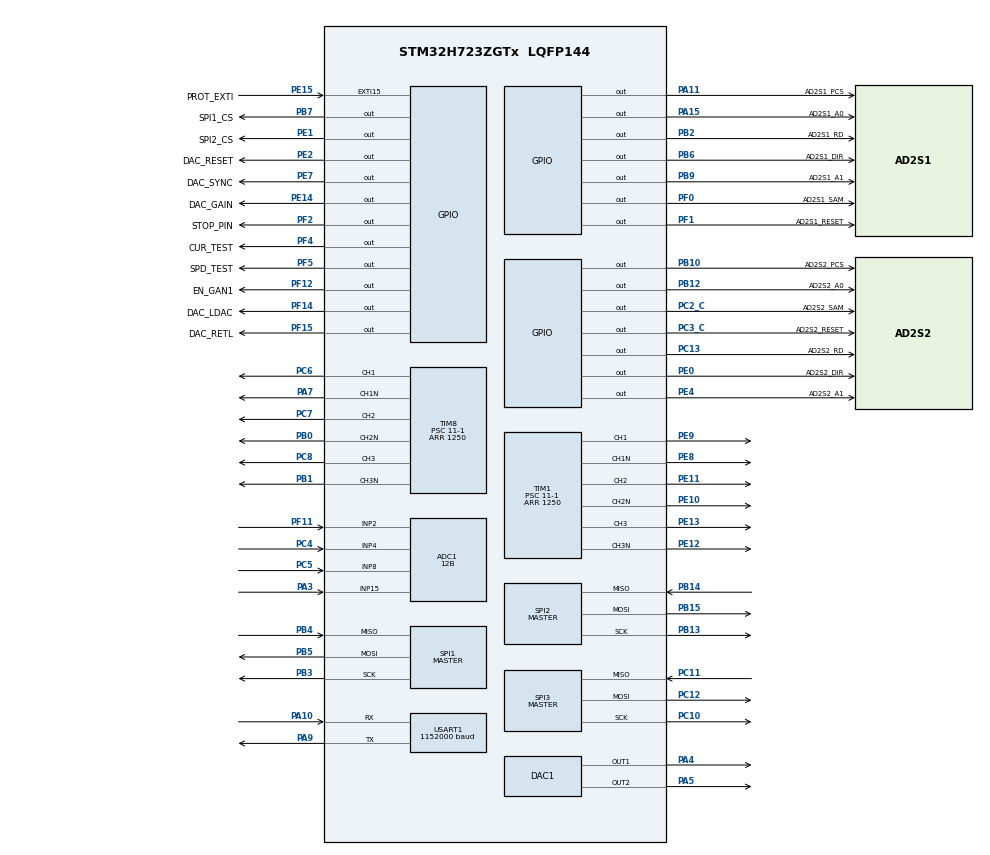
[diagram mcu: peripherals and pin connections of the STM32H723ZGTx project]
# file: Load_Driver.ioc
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ADC1.Channel-0\#ChannelRegularConversion=ADC_CHANNEL_2
ADC1.Channel-1\#ChannelRegularConversion=ADC_CHANNEL_8
ADC1.Channel-2\#ChannelRegularConversion=ADC_CHANNEL_4
ADC1.Channel-3\#ChannelRegularConversion=ADC_CHANNEL_15
ADC1.ClockPrescaler=ADC_CLOCK_ASYNC_DIV4
ADC1.ConversionDataManagement=ADC_CONVERSIONDATA_DMA_CIRCULAR
ADC1.ExternalTrigConv=ADC_EXTERNALTRIG_T1_TRGO
ADC1.NbrOfConversion=4
ADC1.NbrOfConversionFlag=1
ADC1.OffsetNumber-0\#ChannelRegularConversion=ADC_OFFSET_NONE
ADC1.OffsetNumber-1\#ChannelRegularConversion=ADC_OFFSET_NONE
ADC1.OffsetNumber-2\#ChannelRegularConversion=ADC_OFFSET_NONE
ADC1.OffsetNumber-3\#ChannelRegularConversion=ADC_OFFSET_NONE
ADC1.OffsetSignedSaturation-0\#ChannelRegularConversion=DISABLE
ADC1.Rank-0\#ChannelRegularConversion=1
ADC1.Rank-1\#ChannelRegularConversion=2
ADC1.Rank-2\#ChannelRegularConversion=3
ADC1.Rank-3\#ChannelRegularConversion=4
ADC1.Resolution=ADC_RESOLUTION_12B
ADC1.SamplingTime-0\#ChannelRegularConversion=ADC_SAMPLETIME_2CYCLES_5
ADC1.SamplingTime-1\#ChannelRegularConversion=ADC_SAMPLETIME_2CYCLES_5
ADC1.SamplingTime-2\#ChannelRegularConversion=ADC_SAMPLETIME_2CYCLES_5
ADC1.SamplingTime-3\#ChannelRegularConversion=ADC_SAMPLETIME_2CYCLES_5
ADC1.master=1
CORTEX_M7.default_mode_Activation=1
DAC1.DAC_Channel-DAC_OUT1=DAC_CHANNEL_1
DAC1.DAC_Channel-DAC_OUT2=DAC_CHANNEL_2
DAC1.DAC_Trigger-DAC_OUT1=DAC_TRIGGER_T1_TRGO
DAC1.DAC_Trigger-DAC_OUT2=DAC_TRIGGER_T1_TRGO
Dma.ADC1.0.Direction=DMA_PERIPH_TO_MEMORY
Dma.ADC1.0.EventEnable=DISABLE
Dma.ADC1.0.FIFOMode=DMA_FIFOMODE_DISABLE
Dma.ADC1.0.Instance=DMA1_Stream0
Dma.ADC1.0.MemDataAlignment=DMA_MDATAALIGN_HALFWORD
Dma.ADC1.0.MemInc=DMA_MINC_ENABLE
Dma.ADC1.0.Mode=DMA_CIRCULAR
Dma.ADC1.0.PeriphDataAlignment=DMA_PDATAALIGN_HALFWORD
Dma.ADC1.0.PeriphInc=DMA_PINC_DISABLE
Dma.ADC1.0.Polarity=HAL_DMAMUX_REQ_GEN_RISING
Dma.ADC1.0.Priority=DMA_PRIORITY_LOW
Dma.ADC1.0.RequestNumber=1
Dma.ADC1.0.SignalID=NONE
Dma.ADC1.0.SyncEnable=DISABLE
Dma.ADC1.0.SyncPolarity=HAL_DMAMUX_SYNC_NO_EVENT
Dma.ADC1.0.SyncRequestNumber=1
Dma.ADC1.0.SyncSignalID=NONE
Dma.Request0=ADC1
Mcu.Family=STM32H7
Mcu.Name=STM32H723ZGTx
Mcu.Package=LQFP144
NVIC.DMA1_Stream0_IRQn=true\:1\:0\:true\:false\:true\:false\:true\:true
NVIC.EXTI15_10_IRQn=true\:0\:0\:false\:false\:true\:true\:true\:true
NVIC.PriorityGroup=NVIC_PRIORITYGROUP_4
PA10.Mode=Asynchronous
PA10.Signal=USART1_RX
PA11.GPIO_Label=AD2S1_PCS
PA11.GPIO_PuPd=GPIO_PULLUP
PA11.GPIO_Speed=GPIO_SPEED_FREQ_HIGH
PA11.PinState=GPIO_PIN_SET
PA11.Signal=GPIO_Output
PA13(JTMS/SWDIO).Mode=Serial_Wire
PA13(JTMS/SWDIO).Signal=DEBUG_JTMS-SWDIO
PA14(JTCK/SWCLK).Mode=Serial_Wire
PA14(JTCK/SWCLK).Signal=DEBUG_JTCK-SWCLK
PA15(JTDI).GPIO_Label=AD2S1_A0
PA15(JTDI).GPIO_PuPd=GPIO_PULLUP
PA15(JTDI).PinState=GPIO_PIN_RESET
PA15(JTDI).Signal=GPIO_Output
PA3.Signal=ADCx_INP15
PA4.Signal=COMP_DAC11_group
PA5.Signal=COMP_DAC12_group
PA7.Mode=PWM Generation1 CH1 CH1N
PA7.Signal=TIM8_CH1N
PA9.Mode=Asynchronous
PA9.Signal=USART1_TX
PB0.Mode=PWM Generation2 CH2 CH2N
PB0.Signal=TIM8_CH2N
PB1.Mode=PWM Generation3 CH3 CH3N
PB1.Signal=TIM8_CH3N
PB10.GPIO_Label=AD2S2_PCS
PB10.GPIO_PuPd=GPIO_PULLUP
PB10.PinState=GPIO_PIN_SET
PB10.Signal=GPIO_Output
PB12.GPIO_Label=AD2S2_A0
PB12.GPIO_PuPd=GPIO_PULLUP
PB12.Signal=GPIO_Output
PB13.Mode=Full_Duplex_Master
PB13.Signal=SPI2_SCK
PB14.Mode=Full_Duplex_Master
PB14.Signal=SPI2_MISO
PB15.Mode=Full_Duplex_Master
PB15.Signal=SPI2_MOSI
PB2.GPIO_Label=AD2S1_RD
PB2.GPIO_PuPd=GPIO_PULLUP
PB2.PinState=GPIO_PIN_SET
PB2.Signal=GPIO_Output
PB3(JTDO/TRACESWO).Mode=Full_Duplex_Master
PB3(JTDO/TRACESWO).Signal=SPI1_SCK
PB4(NJTRST).Mode=Full_Duplex_Master
PB4(NJTRST).Signal=SPI1_MISO
PB5.Mode=Full_Duplex_Master
PB5.Signal=SPI1_MOSI
PB6.GPIO_Label=AD2S1_DIR
PB6.GPIO_PuPd=GPIO_PULLUP
PB6.Signal=GPIO_Output
PB7.GPIO_Label=SPI1_CS
PB7.GPIO_PuPd=GPIO_PULLUP
PB7.GPIO_Speed=GPIO_SPEED_FREQ_HIGH
PB7.PinState=GPIO_PIN_SET
PB7.Signal=GPIO_Output
PB9.GPIO_Label=AD2S1_A1
PB9.GPIO_PuPd=GPIO_PULLUP
PB9.Signal=GPIO_Output
PC10.Mode=Full_Duplex_Master
PC10.Signal=SPI3_SCK
PC11.Mode=Full_Duplex_Master
PC11.Signal=SPI3_MISO
PC12.Mode=Full_Duplex_Master
PC12.Signal=SPI3_MOSI
PC13.GPIO_Label=AD2S2_RD
PC13.GPIO_PuPd=GPIO_PULLUP
PC13.PinState=GPIO_PIN_SET
PC13.Signal=GPIO_Output
PC2_C.GPIO_Label=AD2S2_SAM
PC2_C.GPIO_PuPd=GPIO_PULLUP
PC2_C.Signal=GPIO_Output
PC3_C.GPIO_Label=AD2S2_RESET
PC3_C.GPIO_PuPd=GPIO_PULLUP
PC3_C.Signal=GPIO_Output
PC4.Signal=ADCx_INP4
PC5.Signal=ADCx_INP8
PC6.Signal=S_TIM8_CH1
PC7.Signal=S_TIM8_CH2
PC8.Signal=S_TIM8_CH3
PE0.GPIO_Label=AD2S2_DIR
PE0.GPIO_PuPd=GPIO_PULLUP
PE0.Signal=GPIO_Output
PE1.GPIO_Label=SPI2_CS
PE1.GPIO_PuPd=GPIO_PULLUP
PE1.PinState=GPIO_PIN_SET
PE1.Signal=GPIO_Output
PE10.Mode=PWM Generation2 CH2 CH2N
PE10.Signal=TIM1_CH2N
PE11.Signal=S_TIM1_CH2
PE12.Mode=PWM Generation3 CH3 CH3N
PE12.Signal=TIM1_CH3N
PE13.Signal=S_TIM1_CH3
PE14.GPIO_Label=DAC_GAIN
PE14.GPIO_PuPd=GPIO_PULLUP
PE14.Signal=GPIO_Output
PE15.GPIO_Label=PROT_EXTI
PE15.GPIO_ModeDefaultEXTI=GPIO_MODE_IT_FALLING
PE15.GPIO_PuPd=GPIO_PULLUP
PE15.Signal=GPXTI15
PE2.GPIO_Label=DAC_RESET
PE2.GPIO_PuPd=GPIO_PULLUP
PE2.Signal=GPIO_Output
PE4.GPIO_Label=AD2S2_A1
PE4.GPIO_PuPd=GPIO_PULLUP
PE4.Signal=GPIO_Output
PE7.GPIO_Label=DAC_SYNC
PE7.GPIO_PuPd=GPIO_PULLUP
PE7.Signal=GPIO_Output
PE8.Mode=PWM Generation1 CH1 CH1N
PE8.Signal=TIM1_CH1N
PE9.Signal=S_TIM1_CH1
PF0.GPIO_Label=AD2S1_SAM
PF0.GPIO_PuPd=GPIO_PULLUP
PF0.GPIO_Speed=GPIO_SPEED_FREQ_HIGH
PF0.Signal=GPIO_Output
PF1.GPIO_Label=AD2S1_RESET
PF1.GPIO_PuPd=GPIO_PULLUP
PF1.PinState=GPIO_PIN_SET
PF1.Signal=GPIO_Output
PF11.Mode=IN2-Single-Ended
PF11.Signal=ADC1_INP2
PF12.GPIO_Label=EN_GAN1
PF12.GPIO_PuPd=GPIO_PULLUP
PF12.Signal=GPIO_Output
PF14.GPIO_Label=DAC_LDAC
PF14.GPIO_PuPd=GPIO_PULLUP
PF14.Signal=GPIO_Output
PF15.GPIO_Label=DAC_RETL
PF15.GPIO_PuPd=GPIO_PULLUP
PF15.Signal=GPIO_Output
PF2.GPIO_Label=STOP_PIN
PF2.GPIO_PuPd=GPIO_PULLUP
PF2.PinState=GPIO_PIN_SET
PF2.Signal=GPIO_Output
PF4.GPIO_Label=CUR_TEST
PF4.GPIO_PuPd=GPIO_PULLUP
PF4.Signal=GPIO_Output
PF5.GPIO_Label=SPD_TEST
PF5.GPIO_PuPd=GPIO_PULLUP
PF5.Signal=GPIO_Output
PH0-OSC_IN.Mode=HSE-External-Oscillator
PH0-OSC_IN.Signal=RCC_OSC_IN
PH1-OSC_OUT.Mode=HSE-External-Oscillator
PH1-OSC_OUT.Signal=RCC_OSC_OUT
ProjectManager.HeapSize=0x200
ProjectManager.StackSize=0x400
ProjectManager.TargetToolchain=MDK-ARM V5.32
RCC.ADCFreq_Value=100000000
RCC.APB1Freq_Value=137500000
RCC.APB2Freq_Value=137500000
RCC.APB3Freq_Value=137500000
RCC.APB4Freq_Value=137500000
RCC.CortexFreq_Value=550000000
RCC.D1PPRE=RCC_APB3_DIV2
RCC.D2PPRE1=RCC_APB1_DIV2
RCC.D2PPRE2=RCC_APB2_DIV2
RCC.D3PPRE=RCC_APB4_DIV2
RCC.DIVM1=2
RCC.DIVM2=2
RCC.DIVN1=44
RCC.DIVN2=16
RCC.DIVP1=1
RCC.DIVQ1=3
RCC.HCLKFreq_Value=275000000
RCC.HPRE=RCC_HCLK_DIV2
RCC.PLL2FRACN=0
RCC.PLLFRACN=0
RCC.PLLSourceVirtual=RCC_PLLSOURCE_HSE
RCC.SYSCLKFreq_VALUE=550000000
RCC.SYSCLKSource=RCC_SYSCLKSOURCE_PLLCLK
RCC.USBFreq_Value=183333333.33333334
SH.ADCx_INP15.0=ADC1_INP15,IN15-Single-Ended
SH.ADCx_INP4.0=ADC1_INP4,IN4-Single-Ended
SH.ADCx_INP8.0=ADC1_INP8,IN8-Single-Ended
SH.COMP_DAC11_group.0=DAC1_OUT1,DAC_OUT1
SH.COMP_DAC12_group.0=DAC1_OUT2,DAC_OUT2
SH.S_TIM1_CH1.0=TIM1_CH1,PWM Generation1 CH1 CH1N
SH.S_TIM1_CH2.0=TIM1_CH2,PWM Generation2 CH2 CH2N
SH.S_TIM1_CH3.0=TIM1_CH3,PWM Generation3 CH3 CH3N
SH.S_TIM8_CH1.0=TIM8_CH1,PWM Generation1 CH1 CH1N
SH.S_TIM8_CH2.0=TIM8_CH2,PWM Generation2 CH2 CH2N
SH.S_TIM8_CH3.0=TIM8_CH3,PWM Generation3 CH3 CH3N
SPI1.BaudRatePrescaler=SPI_BAUDRATEPRESCALER_16
SPI1.CLKPhase=SPI_PHASE_2EDGE
SPI1.CalculateBaudRate=11.458333 MBits/s
SPI1.DataSize=SPI_DATASIZE_8BIT
SPI1.Direction=SPI_DIRECTION_2LINES
SPI1.Mode=SPI_MODE_MASTER
SPI1.VirtualType=VM_MASTER
SPI2.BaudRatePrescaler=SPI_BAUDRATEPRESCALER_16
SPI2.CLKPhase=SPI_PHASE_2EDGE
SPI2.CalculateBaudRate=11.458333 MBits/s
SPI2.DataSize=SPI_DATASIZE_8BIT
SPI2.Direction=SPI_DIRECTION_2LINES
SPI2.Mode=SPI_MODE_MASTER
SPI2.VirtualType=VM_MASTER
SPI3.BaudRatePrescaler=SPI_BAUDRATEPRESCALER_16
SPI3.CLKPhase=SPI_PHASE_2EDGE
SPI3.CalculateBaudRate=11.458333 MBits/s
SPI3.DataSize=SPI_DATASIZE_8BIT
SPI3.Direction=SPI_DIRECTION_2LINES
SPI3.Mode=SPI_MODE_MASTER
SPI3.VirtualType=VM_MASTER
TIM1.Channel-PWM\ Generation1\ CH1\ CH1N=TIM_CHANNEL_1
TIM1.Channel-PWM\ Generation2\ CH2\ CH2N=TIM_CHANNEL_2
TIM1.Channel-PWM\ Generation3\ CH3\ CH3N=TIM_CHANNEL_3
TIM1.DeadTime=230
TIM1.OCFastMode_PWM-PWM\ Generation1\ CH1\ CH1N=TIM_OCFAST_ENABLE
TIM1.OCFastMode_PWM-PWM\ Generation2\ CH2\ CH2N=TIM_OCFAST_ENABLE
TIM1.OCFastMode_PWM-PWM\ Generation3\ CH3\ CH3N=TIM_OCFAST_ENABLE
TIM1.Period=1250
TIM1.Prescaler=11-1
TIM1.RepetitionCounter=1
TIM1.TIM_MasterOutputTrigger=TIM_TRGO_UPDATE
TIM1.TIM_MasterOutputTrigger2=TIM_TRGO2_RESET
TIM7.Period=1
TIM7.Prescaler=275-1
TIM8.Channel-PWM\ Generation1\ CH1\ CH1N=TIM_CHANNEL_1
TIM8.Channel-PWM\ Generation2\ CH2\ CH2N=TIM_CHANNEL_2
TIM8.Channel-PWM\ Generation3\ CH3\ CH3N=TIM_CHANNEL_3
TIM8.DeadTime=230
TIM8.OCFastMode_PWM-PWM\ Generation1\ CH1\ CH1N=TIM_OCFAST_ENABLE
TIM8.OCFastMode_PWM-PWM\ Generation2\ CH2\ CH2N=TIM_OCFAST_ENABLE
TIM8.OCFastMode_PWM-PWM\ Generation3\ CH3\ CH3N=TIM_OCFAST_ENABLE
TIM8.Period=1250
TIM8.Prescaler=11-1
TIM8.RepetitionCounter=1
USART1.BaudRate=1152000
USART1.VirtualMode-Asynchronous=VM_ASYNC
VP_MEMORYMAP_VS_MEMORYMAP.Mode=CurAppReg
VP_TIM1_VS_ClockSourceINT.Mode=Internal
VP_TIM7_VS_ClockSourceINT.Mode=Enable_Timer
VP_TIM8_VS_ClockSourceINT.Mode=Internal
board=custom

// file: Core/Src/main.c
/* USER CODE BEGIN Header */
/**
  ******************************************************************************
  * @file           : main.c
  * @brief          : Main program body
  ******************************************************************************
  * @attention
  *
  * Copyright (c) 2026 STMicroelectronics.
  * All rights reserved.
  *
  * This software is licensed under terms that can be found in the LICENSE file
  * in the root directory of this software component.
  * If no LICENSE file comes with this software, it is provided AS-IS.
  *
  ******************************************************************************
  */
/* USER CODE END Header */
#include "main.h"
#include "adc.h"
#include "dac.h"
#include "dma.h"
#include "memorymap.h"
#include "spi.h"
#include "tim.h"
#include "usart.h"
#include "gpio.h"

/* USER CODE BEGIN Includes */
#include "usermain.h"
/* USER CODE END Includes */

void SystemClock_Config(void);
static void MPU_Config(void);

int main(void)
{

  /* MPU Configuration--------------------------------------------------------*/
  MPU_Config();

  /* MCU Configuration--------------------------------------------------------*/

  /* Reset of all peripherals, Initializes the Flash interface and the Systick. */
  HAL_Init();

  /* Configure the system clock */
  SystemClock_Config();

  /* Initialize all configured peripherals */
  MX_GPIO_Init();
  MX_DMA_Init();
  MX_TIM1_Init();
  MX_TIM8_Init();
  MX_ADC1_Init();
  MX_SPI1_Init();
  MX_SPI2_Init();
  MX_SPI3_Init();
  MX_DAC1_Init();
  MX_USART1_UART_Init();
  MX_TIM7_Init();
  /* USER CODE BEGIN 2 */
  usermain();
  /* USER CODE END 2 */

  /* Infinite loop */
  while (1)
  {

  }
}

void SystemClock_Config(void)
{
  RCC_OscInitTypeDef RCC_OscInitStruct = {0};
  RCC_ClkInitTypeDef RCC_ClkInitStruct = {0};

  /** Supply configuration update enable
  */
  HAL_PWREx_ConfigSupply(PWR_LDO_SUPPLY);

  /** Configure the main internal regulator output voltage
  */
  __HAL_PWR_VOLTAGESCALING_CONFIG(PWR_REGULATOR_VOLTAGE_SCALE0);

  while(!__HAL_PWR_GET_FLAG(PWR_FLAG_VOSRDY)) {}

  /** Initializes the RCC Oscillators according to the specified parameters
  * in the RCC_OscInitTypeDef structure.
  */
  RCC_OscInitStruct.OscillatorType = RCC_OSCILLATORTYPE_HSE;
  RCC_OscInitStruct.HSEState = RCC_HSE_ON;
  RCC_OscInitStruct.PLL.PLLState = RCC_PLL_ON;
  RCC_OscInitStruct.PLL.PLLSource = RCC_PLLSOURCE_HSE;
  RCC_OscInitStruct.PLL.PLLM = 2;
  RCC_OscInitStruct.PLL.PLLN = 44;
  RCC_OscInitStruct.PLL.PLLP = 1;
  RCC_OscInitStruct.PLL.PLLQ = 3;
  RCC_OscInitStruct.PLL.PLLR = 2;
  RCC_OscInitStruct.PLL.PLLRGE = RCC_PLL1VCIRANGE_3;
  RCC_OscInitStruct.PLL.PLLVCOSEL = RCC_PLL1VCOWIDE;
  RCC_OscInitStruct.PLL.PLLFRACN = 0;
  if (HAL_RCC_OscConfig(&RCC_OscInitStruct) != HAL_OK)
  {
    Error_Handler();
  }

  /** Initializes the CPU, AHB and APB buses clocks
  */
  RCC_ClkInitStruct.ClockType = RCC_CLOCKTYPE_HCLK|RCC_CLOCKTYPE_SYSCLK
                              |RCC_CLOCKTYPE_PCLK1|RCC_CLOCKTYPE_PCLK2
                              |RCC_CLOCKTYPE_D3PCLK1|RCC_CLOCKTYPE_D1PCLK1;
  RCC_ClkInitStruct.SYSCLKSource = RCC_SYSCLKSOURCE_PLLCLK;
  RCC_ClkInitStruct.SYSCLKDivider = RCC_SYSCLK_DIV1;
  RCC_ClkInitStruct.AHBCLKDivider = RCC_HCLK_DIV2;
  RCC_ClkInitStruct.APB3CLKDivider = RCC_APB3_DIV2;
  RCC_ClkInitStruct.APB1CLKDivider = RCC_APB1_DIV2;
  RCC_ClkInitStruct.APB2CLKDivider = RCC_APB2_DIV2;
  RCC_ClkInitStruct.APB4CLKDivider = RCC_APB4_DIV2;

  if (HAL_RCC_ClockConfig(&RCC_ClkInitStruct, FLASH_LATENCY_3) != HAL_OK)
  {
    Error_Handler();
  }
}

 /* MPU Configuration */

void MPU_Config(void)
{
  MPU_Region_InitTypeDef MPU_InitStruct = {0};

  /* Disables the MPU */
  HAL_MPU_Disable();

  /** Initializes and configures the Region and the memory to be protected
  */
  MPU_InitStruct.Enable = MPU_REGION_ENABLE;
  MPU_InitStruct.Number = MPU_REGION_NUMBER0;
  MPU_InitStruct.BaseAddress = 0x0;
  MPU_InitStruct.Size = MPU_REGION_SIZE_4GB;
  MPU_InitStruct.SubRegionDisable = 0x87;
  MPU_InitStruct.TypeExtField = MPU_TEX_LEVEL0;
  MPU_InitStruct.AccessPermission = MPU_REGION_NO_ACCESS;
  MPU_InitStruct.DisableExec = MPU_INSTRUCTION_ACCESS_DISABLE;
  MPU_InitStruct.IsShareable = MPU_ACCESS_SHAREABLE;
  MPU_InitStruct.IsCacheable = MPU_ACCESS_NOT_CACHEABLE;
  MPU_InitStruct.IsBufferable = MPU_ACCESS_NOT_BUFFERABLE;

  HAL_MPU_ConfigRegion(&MPU_InitStruct);
  /* Enables the MPU */
  HAL_MPU_Enable(MPU_PRIVILEGED_DEFAULT);

}

void Error_Handler(void)
{
  __disable_irq();
  while (1)
  {
  }
}
